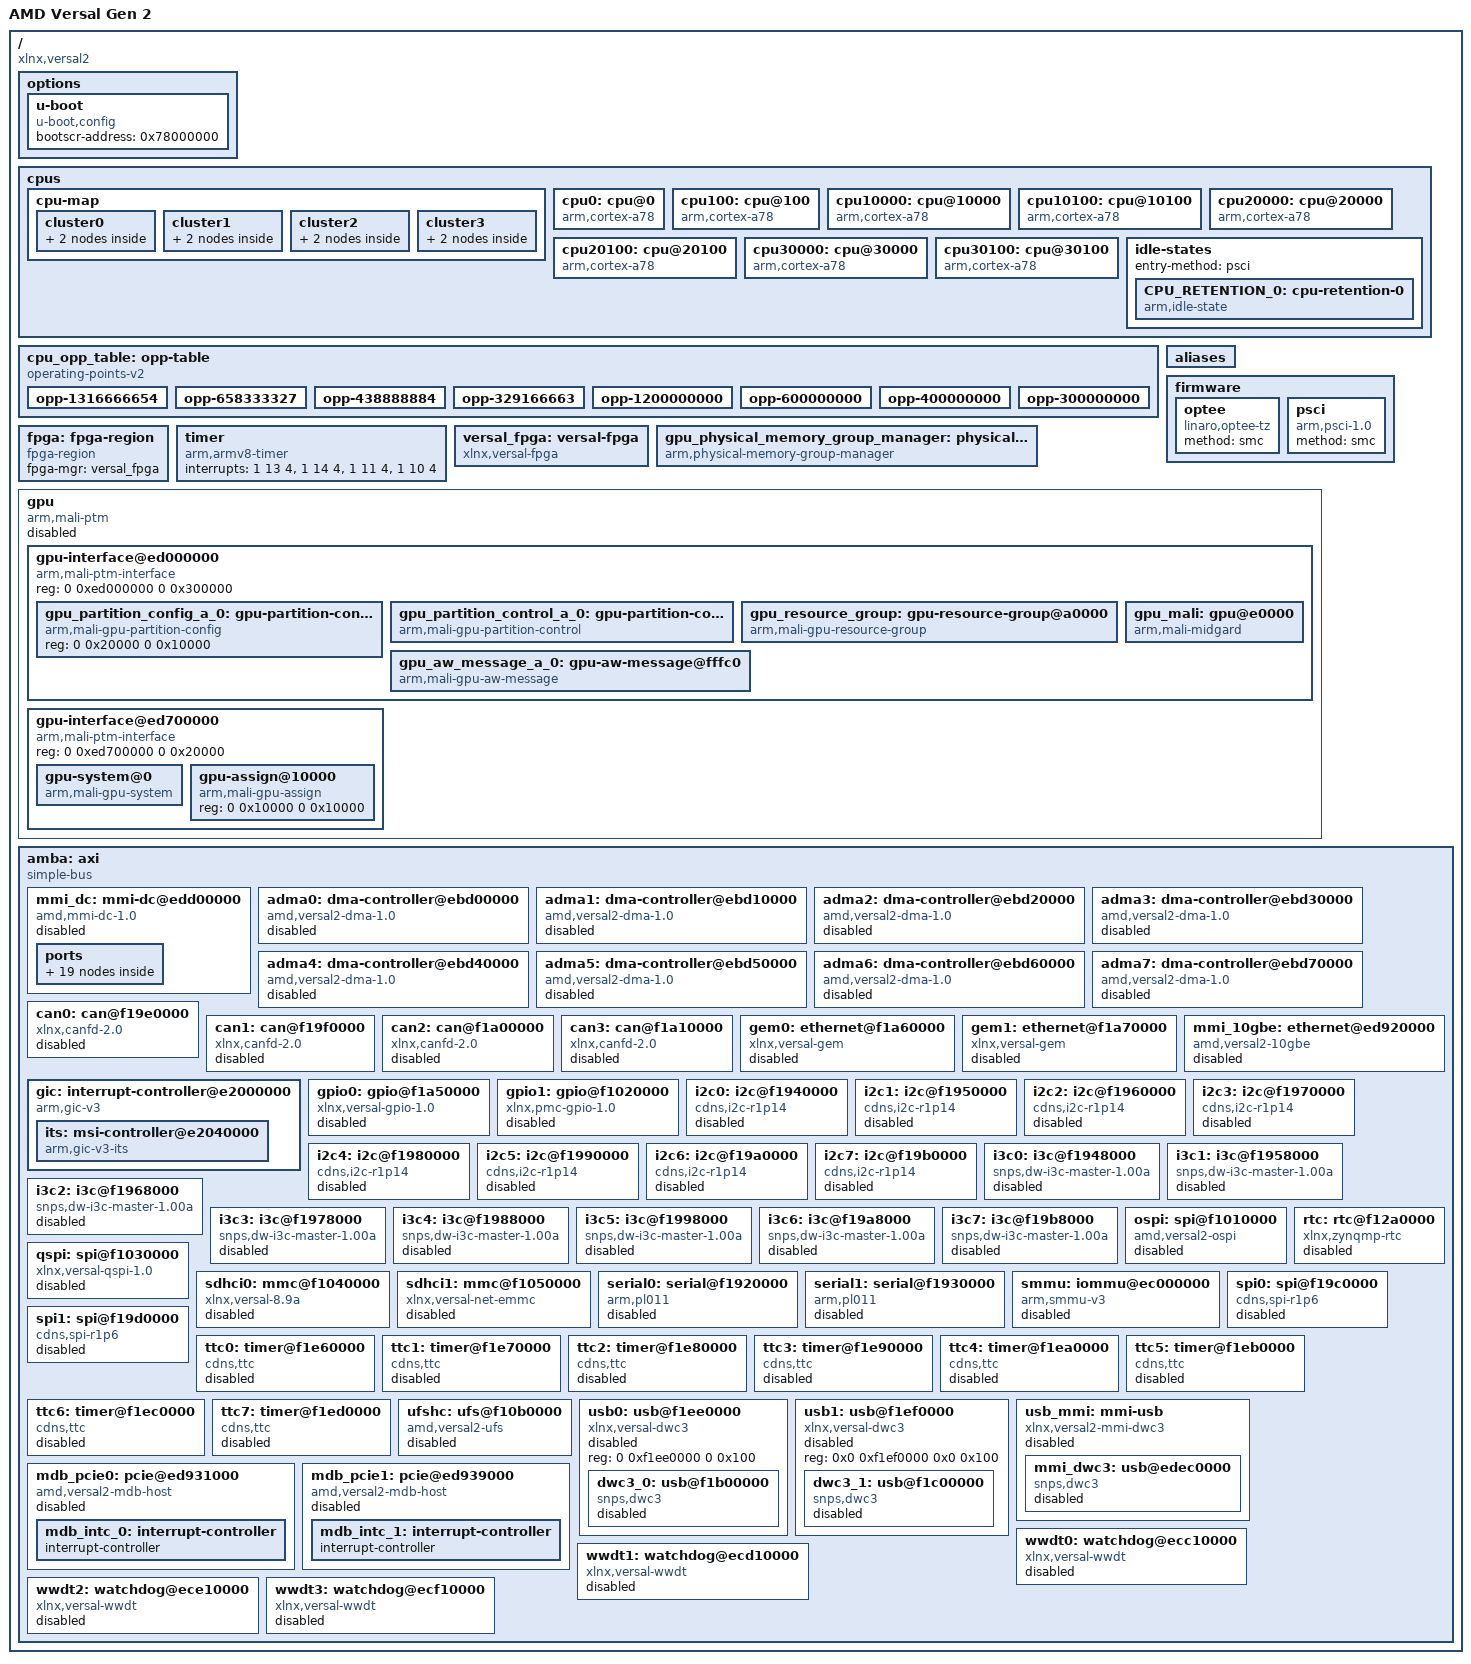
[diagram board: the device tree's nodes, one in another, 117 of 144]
// SPDX-License-Identifier: GPL-2.0
/*
 * dts file for AMD Versal Gen 2
 *
 * Copyright (C) 2023 - 2025, Advanced Micro Devices, Inc.
 *
 * Michal Simek <michal.simek@amd.com>
 */

/dts-v1/;

/ {
	compatible = "xlnx,versal2";
	model = "AMD Versal Gen 2";
	#address-cells = <2>;
	#size-cells = <2>;
	interrupt-parent = <&gic>;

	options {
		u-boot {
			compatible = "u-boot,config";
			bootscr-address = /bits/ 64 <0x78000000>;
		};
	};

	cpus {
		#address-cells = <1>;
		#size-cells = <0>;
		cpu-map {
			cluster0 {
				core0 {
					cpu = <&cpu0>;
				};
				core1 {
					cpu = <&cpu100>;
				};
			};
			cluster1 {
				core0 {
					cpu = <&cpu10000>;
				};
				core1 {
					cpu = <&cpu10100>;
				};
			};
			cluster2 {
				core0 {
					cpu = <&cpu20000>;
				};
				core1 {
					cpu = <&cpu20100>;
				};
			};
			cluster3 {
				core0 {
					cpu = <&cpu30000>;
				};
				core1 {
					cpu = <&cpu30100>;
				};
			};
		};

		cpu0: cpu@0 {
			compatible = "arm,cortex-a78";
			device_type = "cpu";
			enable-method = "psci";
			reg = <0>;
			operating-points-v2 = <&cpu_opp_table>;
			cpu-idle-states = <&CPU_RETENTION_0>;
		};
		cpu100: cpu@100 {
			compatible = "arm,cortex-a78";
			device_type = "cpu";
			enable-method = "psci";
			reg = <0x100>;
			operating-points-v2 = <&cpu_opp_table>;
			cpu-idle-states = <&CPU_RETENTION_0>;
		};
		cpu10000: cpu@10000 {
			compatible = "arm,cortex-a78";
			device_type = "cpu";
			enable-method = "psci";
			reg = <0x10000>;
			operating-points-v2 = <&cpu_opp_table>;
			cpu-idle-states = <&CPU_RETENTION_0>;
		};
		cpu10100: cpu@10100 {
			compatible = "arm,cortex-a78";
			device_type = "cpu";
			enable-method = "psci";
			reg = <0x10100>;
			operating-points-v2 = <&cpu_opp_table>;
			cpu-idle-states = <&CPU_RETENTION_0>;
		};
		cpu20000: cpu@20000 {
			compatible = "arm,cortex-a78";
			device_type = "cpu";
			enable-method = "psci";
			reg = <0x20000>;
			operating-points-v2 = <&cpu_opp_table>;
			cpu-idle-states = <&CPU_RETENTION_0>;
		};
		cpu20100: cpu@20100 {
			compatible = "arm,cortex-a78";
			device_type = "cpu";
			enable-method = "psci";
			reg = <0x20100>;
			operating-points-v2 = <&cpu_opp_table>;
			cpu-idle-states = <&CPU_RETENTION_0>;
		};
		cpu30000: cpu@30000 {
			compatible = "arm,cortex-a78";
			device_type = "cpu";
			enable-method = "psci";
			reg = <0x30000>;
			operating-points-v2 = <&cpu_opp_table>;
			cpu-idle-states = <&CPU_RETENTION_0>;
		};
		cpu30100: cpu@30100 {
			compatible = "arm,cortex-a78";
			device_type = "cpu";
			enable-method = "psci";
			reg = <0x30100>;
			operating-points-v2 = <&cpu_opp_table>;
			cpu-idle-states = <&CPU_RETENTION_0>;
		};

		idle-states {
			entry-method = "psci";

			CPU_RETENTION_0: cpu-retention-0 {
				compatible = "arm,idle-state";
				arm,psci-suspend-param = <0>;
				local-timer-stop;
				entry-latency-us = <300>;
				exit-latency-us = <600>;
				min-residency-us = <10000>;
			};
		};
	};

	cpu_opp_table: opp-table {
		compatible = "operating-points-v2";
		opp-1316666654 {
			opp-hz = /bits/ 64 <1316666654>;
			opp-microvolt = <1000000>;
			clock-latency-ns = <500000>;
		};
		opp-658333327 {
			opp-hz = /bits/ 64 <658333327>;
			opp-microvolt = <1000000>;
			clock-latency-ns = <500000>;
		};
		opp-438888884 {
			opp-hz = /bits/ 64 <438888884>;
			opp-microvolt = <1000000>;
			clock-latency-ns = <500000>;
		};
		opp-329166663 {
			opp-hz = /bits/ 64 <329166663>;
			opp-microvolt = <1000000>;
			clock-latency-ns = <500000>;
		};
		opp-1200000000 {
			opp-hz = /bits/ 64 <1200000000>;
			opp-microvolt = <1000000>;
			clock-latency-ns = <500000>;
		};
		opp-600000000 {
			opp-hz = /bits/ 64 <600000000>;
			opp-microvolt = <1000000>;
			clock-latency-ns = <500000>;
		};
		opp-400000000 {
			opp-hz = /bits/ 64 <400000000>;
			opp-microvolt = <1000000>;
			clock-latency-ns = <500000>;
		};
		opp-300000000 {
			opp-hz = /bits/ 64 <300000000>;
			opp-microvolt = <1000000>;
			clock-latency-ns = <500000>;
		};
	};

	aliases {
		serial0 = &serial0;
		serial1 = &serial1;
		mmc0 = &sdhci0;
		mmc1 = &sdhci1;
		i2c0 = &i2c0;
		i2c1 = &i2c1;
		i2c2 = &i2c2;
		i2c3 = &i2c3;
		i2c4 = &i2c4;
		i2c5 = &i2c5;
		i2c6 = &i2c6;
		i2c7 = &i2c7;
		spi0 = &ospi;
		spi1 = &qspi;
		spi2 = &spi0;
		spi3 = &spi1;
	};

	firmware {
		optee: optee { /* Should be injected by firmware */
			compatible = "linaro,optee-tz";
			method = "smc";
		};

		psci: psci { /* Should be injected by firmware */
			compatible = "arm,psci-1.0";
			method = "smc";
		};
	};

	fpga: fpga-region {
		compatible = "fpga-region";
		fpga-mgr = <&versal_fpga>;
		#address-cells = <2>;
		#size-cells = <2>;
	};

	timer: timer {
		compatible = "arm,armv8-timer";
		interrupts = <1 13 4>, <1 14 4>, <1 11 4>, <1 10 4>;
	};

	versal_fpga: versal-fpga {
		compatible = "xlnx,versal-fpga";
	};

	gpu_physical_memory_group_manager: physical-memory-group-manager {
		compatible = "arm,physical-memory-group-manager";
	};

	/*
	 * GPU nodes are based on dt binding document shared by ARM and it will
	 * change going further. Currently as there is no yaml schema available
	 * there are schema errors reported. Till new binding is available
	 * please ignore the DT errors and warnings.
	 */
	gpu: gpu {
		status = "disabled";
		compatible = "arm,mali-ptm", "amd,mmi-gpu";
		ranges;
		#address-cells = <2>;
		#size-cells = <2>;
		xlnx,gpu-slices = <2>;
		xlnx,gpu-clk-freq-mhz = <900000000>;

		gpu-interface@ed000000 {
			compatible = "arm,mali-ptm-interface";
			ranges = <0 0 0 0xed000000 0 0x300000>;
			reg = <0 0xed000000 0 0x300000>;
			#address-cells = <2>;
			#size-cells = <2>;

			gpu_partition_config_a_0: gpu-partition-config@20000 {
				compatible = "arm,mali-gpu-partition-config";
				reg = <0 0x20000 0 0x10000>;
			};

			gpu_partition_control_a_0: gpu-partition-control@30000 {
				compatible = "arm,mali-gpu-partition-control";
				reg = <0 0x30000 0 0x10000>;
				interrupt-names = "PTM_PARTITION_IRQ";
				interrupts = <0 182 4>;
			};

			gpu_resource_group: gpu-resource-group@a0000 {
				compatible = "arm,mali-gpu-resource-group";
				reg = <0 0xa0000 0 0x10000>;
				partition-config = <&gpu_partition_config_a_0>;
				partition-control = <&gpu_partition_control_a_0>;
				interrupt-names = "PTM_GROUP_IRQ";
				interrupts = <0 181 4>;
			};

			gpu_mali: gpu@e0000 {
				compatible = "arm,mali-midgard";
				reg = <0 0xe0000 0 0x1ffc0>;
				interrupt-names = "JOB", "MMU", "GPU";
				interrupts = <0 180 4>, <0 180 4>, <0 180 4>;
				arbiter-if = <&gpu_aw_message_a_0>;
				system-coherency = <0x1f>;
				physical-memory-group-manager =
				<&gpu_physical_memory_group_manager>;
			};

			gpu_aw_message_a_0: gpu-aw-message@fffc0 {
				compatible = "arm,mali-gpu-aw-message";
				reg = <0 0xfffc0 0 0x40>;
				interrupt-names = "PTM_MESSAGE";
				interrupts = <0 180 4>;
			};
		};

		gpu-interface@ed700000 {
			compatible = "arm,mali-ptm-interface";
			ranges = <0 0 0 0xed700000 0 0x20000>;
			reg = <0 0xed700000 0 0x20000>;
			#address-cells = <2>;
			#size-cells = <2>;

			gpu-system@0 {
				compatible = "arm,mali-gpu-system";
				reg = <0 0 0 0x10000>;
				interrupt-names = "PTM_UNCORRECTED_ERROR_IRQ",
						"PTM_DEFERRED_ERROR_IRQ";
				interrupts = <0 188 4>, <0 188 4>;
			};

			gpu-assign@10000 {
				compatible = "arm,mali-gpu-assign";
				reg = <0 0x10000 0 0x10000>;
			};
		};
	};

	amba: axi {
		compatible = "simple-bus";
		bootph-all;
		#address-cells = <2>;
		#size-cells = <2>;
		ranges;

		mmi_dc: mmi-dc@edd00000 {
			compatible = "amd,mmi-dc-1.0";
			status = "disabled";
			reg = <0 0xedd00000 0 0x1000>,
			      <0 0xedd0a000 0 0x1000>,
			      <0 0xedd0b000 0 0x1000>,
			      <0 0xedd0c000 0 0x1000>,
			      <0 0xedd0d000 0 0x1000>;
			reg-names = "dp", "blend", "avbuf", "misc", "irq";
			interrupts = <0 179 4>;
			clock-names = "ps_vid_clk";
			dma-names = "vid.0.0", "vid.0.1", "vid.0.2",
				    "vid.1.0", "vid.1.1", "vid.1.2",
				    "aud", "cur";
			dmas = <&mmi_dcdma 0>, <&mmi_dcdma 1>, <&mmi_dcdma 2>,
			       <&mmi_dcdma 3>, <&mmi_dcdma 4>, <&mmi_dcdma 5>,
			       <&mmi_dcdma 6>, <&mmi_dcdma 7>;

			ports {
				#address-cells = <1>;
				#size-cells = <0>;

				port@0 {
					reg = <0>;
					status = "disabled";
				};
				port@1 {
					reg = <1>;
					status = "disabled";
				};
				port@2 {
					reg = <2>;
					status = "disabled";
				};
				port@3 {
					reg = <3>;
					status = "disabled";
				};
				port@4 {
					reg = <4>;
					status = "disabled";
				};
				port@5 {
					reg = <5>;
					status = "disabled";
				};
				port@6 {
					reg = <6>;
					status = "disabled";
				};
				port@7 {
					reg = <7>;
					status = "disabled";
				};
				port@8 {
					reg = <8>;
					status = "disabled";
				};
				port@9 {
					reg = <9>;
					status = "disabled";
				};
				port@a {
					reg = <10>;
					status = "disabled";
				};
				port@b {
					reg = <11>;
					status = "disabled";
				};
				port@c {
					reg = <12>;
					status = "disabled";
				};
				port@d {
					reg = <13>;
					status = "disabled";
				};
				port@e {
					reg = <14>;
					status = "disabled";
				};
				port@f {
					reg = <15>;
					status = "disabled";
				};
				port@10 {
					reg = <16>;
					status = "disabled";
				};
				port@11 {
					reg = <17>;
					status = "disabled";
				};
				port@12 {
					reg = <18>;
					status = "disabled";
				};
			};
		};

		adma0: dma-controller@ebd00000 {
			compatible = "amd,versal2-dma-1.0";
			status = "disabled";
			reg = <0 0xebd00000 0 0x1000>;
			interrupts = <0 72 4>;
			clock-names = "clk_main", "clk_apb";
			#dma-cells = <1>;
			xlnx,bus-width = <64>;
		};

		adma1: dma-controller@ebd10000 {
			compatible = "amd,versal2-dma-1.0";
			status = "disabled";
			reg = <0 0xebd10000 0 0x1000>;
			interrupts = <0 73 4>;
			clock-names = "clk_main", "clk_apb";
			#dma-cells = <1>;
			xlnx,bus-width = <64>;
		};

		adma2: dma-controller@ebd20000 {
			compatible = "amd,versal2-dma-1.0";
			status = "disabled";
			reg = <0 0xebd20000 0 0x1000>;
			interrupts = <0 74 4>;
			clock-names = "clk_main", "clk_apb";
			#dma-cells = <1>;
			xlnx,bus-width = <64>;
		};

		adma3: dma-controller@ebd30000 {
			compatible = "amd,versal2-dma-1.0";
			status = "disabled";
			reg = <0 0xebd30000 0 0x1000>;
			interrupts = <0 75 4>;
			clock-names = "clk_main", "clk_apb";
			#dma-cells = <1>;
			xlnx,bus-width = <64>;
		};

		adma4: dma-controller@ebd40000 {
			compatible = "amd,versal2-dma-1.0";
			status = "disabled";
			reg = <0 0xebd40000 0 0x1000>;
			interrupts = <0 76 4>;
			clock-names = "clk_main", "clk_apb";
			#dma-cells = <1>;
			xlnx,bus-width = <64>;
		};

		adma5: dma-controller@ebd50000 {
			compatible = "amd,versal2-dma-1.0";
			status = "disabled";
			reg = <0 0xebd50000 0 0x1000>;
			interrupts = <0 77 4>;
			clock-names = "clk_main", "clk_apb";
			#dma-cells = <1>;
			xlnx,bus-width = <64>;
		};

		adma6: dma-controller@ebd60000 {
			compatible = "amd,versal2-dma-1.0";
			status = "disabled";
			reg = <0 0xebd60000 0 0x1000>;
			interrupts = <0 78 4>;
			clock-names = "clk_main", "clk_apb";
			#dma-cells = <1>;
			xlnx,bus-width = <64>;
		};

		adma7: dma-controller@ebd70000 {
			compatible = "amd,versal2-dma-1.0";
			status = "disabled";
			reg = <0 0xebd70000 0 0x1000>;
			interrupts = <0 79 4>;
			clock-names = "clk_main", "clk_apb";
			#dma-cells = <1>;
			xlnx,bus-width = <64>;
		};

		can0: can@f19e0000 {
			compatible = "xlnx,canfd-2.0";
			status = "disabled";
			reg = <0 0xf19e0000 0 0x6000>;
			interrupts = <0 27 4>;
			clock-names = "can_clk", "s_axi_aclk";
			rx-fifo-depth = <64>;
			tx-mailbox-count = <32>;
		};

		can1: can@f19f0000 {
			compatible = "xlnx,canfd-2.0";
			status = "disabled";
			reg = <0 0xf19f0000 0 0x6000>;
			interrupts = <0 28 4>;
			clock-names = "can_clk", "s_axi_aclk";
			rx-fifo-depth = <64>;
			tx-mailbox-count = <32>;
		};

		can2: can@f1a00000 {
			compatible = "xlnx,canfd-2.0";
			status = "disabled";
			reg = <0 0xf1a00000 0 0x6000>;
			interrupts = <0 95 4>;
			clock-names = "can_clk", "s_axi_aclk";
			rx-fifo-depth = <64>;
			tx-mailbox-count = <32>;
		};

		can3: can@f1a10000 {
			compatible = "xlnx,canfd-2.0";
			status = "disabled";
			reg = <0 0xf1a10000 0 0x6000>;
			interrupts = <0 96 4>;
			clock-names = "can_clk", "s_axi_aclk";
			rx-fifo-depth = <64>;
			tx-mailbox-count = <32>;
		};

		gem0: ethernet@f1a60000 {
			compatible = "xlnx,versal-gem", "cdns,gem";
			status = "disabled";
			reg = <0 0xf1a60000 0 0x1000>;
			interrupts = <0 39 4>, <0 39 4>;
			clock-names = "pclk", "hclk", "tx_clk", "rx_clk",
				      "tsu_clk";
		};

		gem1: ethernet@f1a70000 {
			compatible = "xlnx,versal-gem", "cdns,gem";
			status = "disabled";
			reg = <0 0xf1a70000 0 0x1000>;
			interrupts = <0 41 4>, <0 41 4>;
			clock-names = "pclk", "hclk", "tx_clk", "rx_clk",
				      "tsu_clk";
		};

		mmi_10gbe: ethernet@ed920000 {
			compatible = "amd,versal2-10gbe", "cdns,gem";
			status = "disabled";
			reg = <0 0xed920000 0 0x1000>;
			interrupts = <0 164 4>, <0 164 4>, <0 164 4>, <0 164 4>;
			clock-names = "pclk", "hclk", "tx_clk", "tsu_clk";
		};

		gic: interrupt-controller@e2000000 {
			compatible = "arm,gic-v3";
			#interrupt-cells = <3>;
			reg = <0 0xe2000000 0 0x10000>,
			      <0 0xe2060000 0 0x200000>;
			interrupt-controller;
			interrupts = <1 9 4>;
			#address-cells = <2>;
			#size-cells = <2>;
			ranges;
			its: msi-controller@e2040000 {
				compatible = "arm,gic-v3-its";
				msi-controller;
				#msi-cells = <1>;
				reg = <0 0xe2040000 0 0x20000>;
			};
		};

		gpio0: gpio@f1a50000 {
			compatible = "xlnx,versal-gpio-1.0";
			status = "disabled";
			reg = <0 0xf1a50000 0 0x1000>;
			interrupts = <0 20 4>;
			#gpio-cells = <2>;
			gpio-controller;
			#interrupt-cells = <2>;
			interrupt-controller;
		};

		gpio1: gpio@f1020000 {
			compatible = "xlnx,pmc-gpio-1.0";
			status = "disabled";
			reg = <0 0xf1020000 0 0x1000>;
			interrupts = <0 202 4>; /* FIXME */
			#gpio-cells = <2>;
			gpio-controller;
			#interrupt-cells = <2>;
			interrupt-controller;
		};

		i2c0: i2c@f1940000 {
			compatible = "cdns,i2c-r1p14";
			status = "disabled";
			reg = <0 0xf1940000 0 0x1000>;
			interrupts = <0 21 4>;
		};

		i2c1: i2c@f1950000 {
			compatible = "cdns,i2c-r1p14";
			status = "disabled";
			reg = <0 0xf1950000 0 0x1000>;
			interrupts = <0 22 4>;
		};

		i2c2: i2c@f1960000 {
			compatible = "cdns,i2c-r1p14";
			status = "disabled";
			reg = <0 0xf1960000 0 0x1000>;
			interrupts = <0 11 4>;
		};

		i2c3: i2c@f1970000 {
			compatible = "cdns,i2c-r1p14";
			status = "disabled";
			reg = <0 0xf1970000 0 0x1000>;
			interrupts = <0 12 4>;
		};

		i2c4: i2c@f1980000 {
			compatible = "cdns,i2c-r1p14";
			status = "disabled";
			reg = <0 0xf1980000 0 0x1000>;
			interrupts = <0 13 4>;
		};

		i2c5: i2c@f1990000 {
			compatible = "cdns,i2c-r1p14";
			status = "disabled";
			reg = <0 0xf1990000 0 0x1000>;
			interrupts = <0 100 4>;
		};

		i2c6: i2c@f19a0000 {
			compatible = "cdns,i2c-r1p14";
			status = "disabled";
			reg = <0 0xf19a0000 0 0x1000>;
			interrupts = <0 101 4>;
		};

		i2c7: i2c@f19b0000 {
			compatible = "cdns,i2c-r1p14";
			status = "disabled";
			reg = <0 0xf19b0000 0 0x1000>;
			interrupts = <0 102 0x04>;
		};

		i3c0: i3c@f1948000 {
			compatible = "snps,dw-i3c-master-1.00a";
			status = "disabled";
			#address-cells = <3>;
			#size-cells = <0>;
			reg = <0 0xf1948000 0 0x1000>;
			interrupts = <0 21 4>;
		};

		i3c1: i3c@f1958000 {
			compatible = "snps,dw-i3c-master-1.00a";
			status = "disabled";
			#address-cells = <3>;
			#size-cells = <0>;
			reg = <0 0xf1958000 0 0x1000>;
			interrupts = <0 22 4>;
		};

		i3c2: i3c@f1968000 {
			compatible = "snps,dw-i3c-master-1.00a";
			status = "disabled";
			#address-cells = <3>;
			#size-cells = <0>;
			reg = <0 0xf1968000 0 0x1000>;
			interrupts = <0 11 4>;
		};

		i3c3: i3c@f1978000 {
			compatible = "snps,dw-i3c-master-1.00a";
			status = "disabled";
			#address-cells = <3>;
			#size-cells = <0>;
			reg = <0 0xf1978000 0 0x1000>;
			interrupts = <0 12 4>;
		};

		i3c4: i3c@f1988000 {
			compatible = "snps,dw-i3c-master-1.00a";
			status = "disabled";
			#address-cells = <3>;
			#size-cells = <0>;
			reg = <0 0xf1988000 0 0x1000>;
			interrupts = <0 13 4>;
		};

		i3c5: i3c@f1998000 {
			compatible = "snps,dw-i3c-master-1.00a";
			status = "disabled";
			#address-cells = <3>;
			#size-cells = <0>;
			reg = <0 0xf1998000 0 0x1000>;
			interrupts = <0 100 4>;
		};

		i3c6: i3c@f19a8000 {
			compatible = "snps,dw-i3c-master-1.00a";
			status = "disabled";
			#address-cells = <3>;
			#size-cells = <0>;
			reg = <0 0xf19a8000 0 0x1000>;
			interrupts = <0 101 4>;
		};

		i3c7: i3c@f19b8000 {
			compatible = "snps,dw-i3c-master-1.00a";
			status = "disabled";
			#address-cells = <3>;
			#size-cells = <0>;
			reg = <0 0xf19b8000 0 0x1000>;
			interrupts = <0 102 4>;
		};

		ospi: spi@f1010000 {
			compatible = "amd,versal2-ospi", "cdns,qspi-nor";
			status = "disabled";
			reg = <0 0xf1010000 0 0x10000>,
			      <0 0xc0000000 0 0x20000000>;
			interrupts = <0 216 4>;
			cdns,fifo-depth = <256>;
			cdns,fifo-width = <4>;
			cdns,is-dma = <1>; /* u-boot specific */
			cdns,trigger-address = <0xc0000000>;
			clock-names = "ref";
			reset-names = "qspi", "qspi-ocp";
		};

		qspi: spi@f1030000 {
			compatible = "xlnx,versal-qspi-1.0";
			status = "disabled";
			reg = <0 0xf1030000 0 0x1000>; /* missing one more reg range - checking with Sai */
			interrupts = <0 217 4>;
			clock-names = "ref_clk", "pclk";
		};

		rtc: rtc@f12a0000 {
			compatible = "xlnx,zynqmp-rtc";
			status = "disabled";
			reg = <0 0xf12a0000 0 0x100>;
			interrupts = <0 200 4>, <0 201 4>;
			interrupt-names = "alarm", "sec";
			calibration = <0x8000>;
		};

		sdhci0: mmc@f1040000 {
			compatible = "xlnx,versal-8.9a", "arasan,sdhci-8.9a";
			status = "disabled";
			reg = <0 0xf1040000 0 0x10000>;
			interrupts = <0 218 4>;
			clock-names = "clk_xin", "clk_ahb", "gate";
			#clock-cells = <1>;
			clock-output-names = "clk_out_sd0", "clk_in_sd0";
		};

		sdhci1: mmc@f1050000 {
			compatible = "xlnx,versal-net-emmc";
			status = "disabled";
			reg = <0 0xf1050000 0 0x10000>;
			interrupts = <0 220 4>;
			clock-names = "clk_xin", "clk_ahb", "gate";
			#clock-cells = <1>;
			clock-output-names = "clk_out_sd1", "clk_in_sd1";
		};

		serial0: serial@f1920000 {
			bootph-all;
			compatible = "arm,pl011", "arm,primecell";
			status = "disabled";
			reg = <0 0xf1920000 0 0x1000>;
			interrupts = <0 25 4>;
			reg-io-width = <4>;
			clock-names = "uartclk", "apb_pclk";
		};

		serial1: serial@f1930000 {
			bootph-all;
			compatible = "arm,pl011", "arm,primecell";
			status = "disabled";
			reg = <0 0xf1930000 0 0x1000>;
			interrupts = <0 26 4>;
			reg-io-width = <4>;
			clock-names = "uartclk", "apb_pclk";
		};

		smmu: iommu@ec000000 {
			compatible = "arm,smmu-v3";
			status = "disabled";
			reg = <0 0xec000000 0 0x40000>;
			#iommu-cells = <1>;
			interrupt-names = "combined";
			interrupts = <0 169 4>;
			dma-coherent;
		};

		spi0: spi@f19c0000 {
			compatible = "cdns,spi-r1p6";
			status = "disabled";
			interrupts = <0 23 4>;
			reg = <0 0xf19c0000 0 0x1000>;
			clock-names = "ref_clk", "pclk";
		};

		spi1: spi@f19d0000 {
			compatible = "cdns,spi-r1p6";
			status = "disabled";
			interrupts = <0 24 4>;
			reg = <0 0xf19d0000 0 0x1000>;
			clock-names = "ref_clk", "pclk";
		};

		ttc0: timer@f1e60000 {
			compatible = "cdns,ttc";
			status = "disabled";
			interrupts = <0 43 4>, <0 43 4>, <0 43 4>;
			timer-width = <32>;
			reg = <0 0xf1e60000 0x0 0x1000>;
		};

		ttc1: timer@f1e70000 {
			compatible = "cdns,ttc";
			status = "disabled";
			interrupts = <0 44 4>, <0 44 4>, <0 44 4>;
			timer-width = <32>;
			reg = <0 0xf1e70000 0 0x1000>;
		};

		ttc2: timer@f1e80000 {
			compatible = "cdns,ttc";
			status = "disabled";
			interrupts = <0 45 4>, <0 45 4>, <0 45 4>;
			timer-width = <32>;
			reg = <0 0xf1e80000 0 0x1000>;
		};

		ttc3: timer@f1e90000 {
			compatible = "cdns,ttc";
			status = "disabled";
			interrupts = <0 46 4>, <0 46 4>, <0 46 4>;
			timer-width = <32>;
			reg = <0 0xf1e90000 0 0x1000>;
		};

		ttc4: timer@f1ea0000 {
			compatible = "cdns,ttc";
			status = "disabled";
			interrupts = <0 47 4>, <0 47 4>, <0 47 4>;
			timer-width = <32>;
			reg = <0 0xf1ea0000 0 0x1000>;
		};

		ttc5: timer@f1eb0000 {
			compatible = "cdns,ttc";
			status = "disabled";
			interrupts = <0 48 4>, <0 48 4>, <0 48 4>;
			timer-width = <32>;
			reg = <0 0xf1eb0000 0 0x1000>;
		};

		ttc6: timer@f1ec0000 {
			compatible = "cdns,ttc";
			status = "disabled";
			interrupts = <0 49 4>, <0 49 4>, <0 49 4>;
			timer-width = <32>;
			reg = <0 0xf1ec0000 0 0x1000>;
		};

		ttc7: timer@f1ed0000 {
			compatible = "cdns,ttc";
			status = "disabled";
			interrupts = <0 50 4>, <0 50 4>, <0 50 4>;
			timer-width = <32>;
			reg = <0 0xf1ed0000 0 0x1000>;
		};

		ufshc: ufs@f10b0000 {
			compatible = "amd,versal2-ufs";
			status = "disabled";
			interrupts = <0 234 4>;
			reg = <0 0xf10b0000 0 0x100>;
			freq-table-hz = <0 0>;
			clock-names = "core_clk";
			reset-names = "ufshc-rst", "ufsphy-rst";
		};

		usb0: usb@f1ee0000 {
			compatible = "xlnx,versal-dwc3";
			status = "disabled";
			reg = <0 0xf1ee0000 0 0x100>;
			clock-names = "bus_clk", "ref_clk";
			reset-names = "usb_crst";
			ranges;
			#address-cells = <2>;
			#size-cells = <2>;

			dwc3_0: usb@f1b00000  {
				compatible = "snps,dwc3";
				status = "disabled";
				reg = <0 0xf1b00000 0 0x10000>;
				interrupt-names = "host", "peripheral", "otg", "wakeup";
				interrupts = <0 29 4>, <0 29 4>, <0 33 4>, <0 98 4>;
				snps,dis_u2_susphy_quirk;
				snps,dis_u3_susphy_quirk;
				snps,quirk-frame-length-adjustment = <0x20>;
				snps,usb3_lpm_capable;
				clock-names = "ref";
			};
		};

		usb1: usb@f1ef0000 {
			compatible = "xlnx,versal-dwc3";
			status = "disabled";
			reg = <0x0 0xf1ef0000 0x0 0x100>;
			clock-names = "bus_clk", "ref_clk";
			reset-names = "usb_crst";
			ranges;
			#address-cells = <2>;
			#size-cells = <2>;

			dwc3_1: usb@f1c00000  {
				compatible = "snps,dwc3";
				status = "disabled";
				reg = <0x0 0xf1c00000 0x0 0x10000>;
				interrupt-names = "host", "peripheral", "otg", "wakeup";
				interrupts = <0 34 4>, <0 34 4>, <0 38 4>, <0 99 4>;
				snps,dis_u2_susphy_quirk;
				snps,dis_u3_susphy_quirk;
				snps,quirk-frame-length-adjustment = <0x20>;
				snps,usb3_lpm_capable;
				clock-names = "ref";
			};
		};

		usb_mmi: mmi-usb {
			compatible = "xlnx,versal2-mmi-dwc3";
			status = "disabled";
			clock-names = "bus_clk", "ref_clk";
			ranges;
			#address-cells = <2>;
			#size-cells = <2>;

			mmi_dwc3: usb@edec0000  {
				compatible = "snps,dwc3";
				status = "disabled";
				reg = <0x0 0xedec0000 0x0 0x10000>;
				interrupt-names = "host", "peripheral";
				interrupts = <0 191 4>, <0 191 4>;
				snps,dis_u2_susphy_quirk;
				snps,dis_u3_susphy_quirk;
				snps,quirk-frame-length-adjustment = <0x20>;
				snps,usb3_lpm_capable;
				dr_mode = "host";
				clock-names = "ref";
			};
		};

		mdb_pcie0: pcie@ed931000 {
			compatible = "amd,versal2-mdb-host";
			status = "disabled";
			reg = <0x0 0xed931000 0x0 0x2000>,
			      <0x1000 0x100000 0x0 0xff00000>,
			      <0x1000 0x0 0x0 0x100000>,
			      <0x0 0xed860000 0x0 0x2000>;
			reg-names = "slcr", "config", "dbi", "atu";
			ranges = <0x2000000 0x00 0xa0000000 0x00 0xa0000000 0x00 0x8000000>,
				 <0x43000000 0x1100 0x00 0x1100 0x00 0x100 0x00>;
			interrupts = <0 165 4>;
			interrupt-map-mask = <0 0 0 7>;
			interrupt-map = <0 0 0 1 &mdb_intc_0 0>,
					<0 0 0 2 &mdb_intc_0 1>,
					<0 0 0 3 &mdb_intc_0 2>,
					<0 0 0 4 &mdb_intc_0 3>;
			msi-map = <0x0 &its 0x00 0x10000>;
			xlnx,num-of-bars = <0x2>;
			xlnx,port-type = <0x1>;
			xlnx,csr-slcr = <0x1000 0x0 0x0>;
			xlnx,iatu-address = <0xed860000>;
			#address-cells = <3>;
			#size-cells = <2>;
			#interrupt-cells = <1>;
			device_type = "pci";
			mdb_intc_0: interrupt-controller {
				#address-cells = <0>;
				#interrupt-cells = <1>;
				interrupt-controller;
			};
		};

		mdb_pcie1: pcie@ed939000 {
			compatible = "amd,versal2-mdb-host";
			status = "disabled";
			reg = <0x0 0xed939000 0x0 0x2000>,
			      <0x1400 0x100000 0x0 0xff00000>,
			      <0x1400 0x0 0x0 0x100000>,
			      <0x0 0xed8e0000 0x0 0x2000>;
			reg-names = "slcr", "config", "dbi", "atu";
			ranges = <0x2000000 0x00 0xa8000000 0x00 0xa8000000 0x00 0x8000000>,
				 <0x43000000 0x1500 0x00 0x1500 0x00 0x100 0x00>;
			interrupts = <0 166 4>;
			interrupt-map-mask = <0 0 0 7>;
			interrupt-map = <0 0 0 1 &mdb_intc_1 0>,
					<0 0 0 2 &mdb_intc_1 1>,
					<0 0 0 3 &mdb_intc_1 2>,
					<0 0 0 4 &mdb_intc_1 3>;
			msi-map = <0x0 &its 0x10000 0x10000>;
			xlnx,num-of-bars = <0x2>;
			xlnx,port-type = <0x1>;
			xlnx,csr-slcr = <0x1400 0x0 0x0>;
			xlnx,iatu-address = <0xed8e0000>;
			#address-cells = <3>;
			#size-cells = <2>;
			#interrupt-cells = <1>;
			device_type = "pci";
			mdb_intc_1: interrupt-controller {
				#address-cells = <0>;
				#interrupt-cells = <1>;
				interrupt-controller;
			};
		};

		wwdt0: watchdog@ecc10000 {
			compatible = "xlnx,versal-wwdt";
			status = "disabled";
			reg = <0 0xecc10000 0 0x10000>;
			timeout-sec = <30>;
		};

		wwdt1: watchdog@ecd10000 {
			compatible = "xlnx,versal-wwdt";
			status = "disabled";
			reg = <0 0xecd10000 0 0x10000>;
			timeout-sec = <30>;
		};

		wwdt2: watchdog@ece10000 {
			compatible = "xlnx,versal-wwdt";
			status = "disabled";
			reg = <0 0xece10000 0 0x10000>;
			timeout-sec = <30>;
		};

		wwdt3: watchdog@ecf10000 {
			compatible = "xlnx,versal-wwdt";
			status = "disabled";
			reg = <0 0xecf10000 0 0x10000>;
			timeout-sec = <30>;
		};
	};
};
